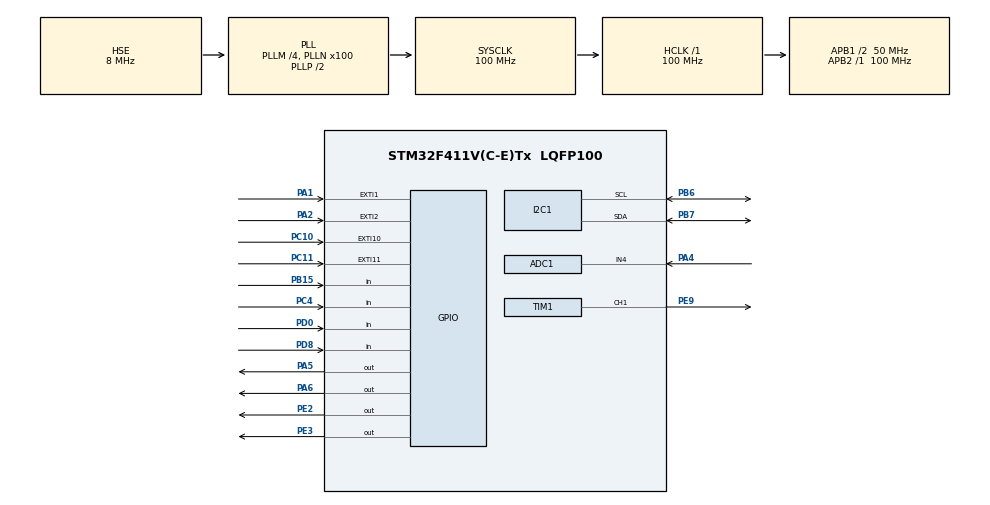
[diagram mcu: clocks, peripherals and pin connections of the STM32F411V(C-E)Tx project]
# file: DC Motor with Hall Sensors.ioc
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ADC1.Channel-0\#ChannelRegularConversion=ADC_CHANNEL_4
ADC1.ContinuousConvMode=ENABLE
ADC1.NbrOfConversion=1
ADC1.NbrOfConversionFlag=1
ADC1.Rank-0\#ChannelRegularConversion=1
ADC1.SamplingTime-0\#ChannelRegularConversion=ADC_SAMPLETIME_3CYCLES
ADC1.ScanConvMode=ENABLE
ADC1.master=1
Dma.ADC1.1.Direction=DMA_PERIPH_TO_MEMORY
Dma.ADC1.1.FIFOMode=DMA_FIFOMODE_DISABLE
Dma.ADC1.1.Instance=DMA2_Stream0
Dma.ADC1.1.MemDataAlignment=DMA_MDATAALIGN_WORD
Dma.ADC1.1.MemInc=DMA_MINC_ENABLE
Dma.ADC1.1.Mode=DMA_CIRCULAR
Dma.ADC1.1.PeriphDataAlignment=DMA_PDATAALIGN_WORD
Dma.ADC1.1.PeriphInc=DMA_PINC_DISABLE
Dma.ADC1.1.Priority=DMA_PRIORITY_LOW
Dma.Request0=TIM1_CH1
Dma.Request1=ADC1
Dma.TIM1_CH1.0.Direction=DMA_MEMORY_TO_PERIPH
Dma.TIM1_CH1.0.FIFOMode=DMA_FIFOMODE_DISABLE
Dma.TIM1_CH1.0.Instance=DMA2_Stream1
Dma.TIM1_CH1.0.MemDataAlignment=DMA_MDATAALIGN_HALFWORD
Dma.TIM1_CH1.0.MemInc=DMA_MINC_ENABLE
Dma.TIM1_CH1.0.Mode=DMA_NORMAL
Dma.TIM1_CH1.0.PeriphDataAlignment=DMA_PDATAALIGN_HALFWORD
Dma.TIM1_CH1.0.PeriphInc=DMA_PINC_DISABLE
Dma.TIM1_CH1.0.Priority=DMA_PRIORITY_LOW
Mcu.Family=STM32F4
Mcu.Name=STM32F411V(C-E)Tx
Mcu.Package=LQFP100
NVIC.ADC_IRQn=true\:0\:0\:false\:false\:true\:true\:true\:true
NVIC.DMA2_Stream0_IRQn=true\:0\:0\:false\:false\:true\:false\:true\:true
NVIC.DMA2_Stream1_IRQn=true\:0\:0\:false\:false\:true\:false\:true\:true
NVIC.EXTI15_10_IRQn=true\:0\:0\:false\:false\:true\:true\:true\:true
NVIC.EXTI1_IRQn=true\:0\:0\:false\:false\:true\:true\:true\:true
NVIC.EXTI2_IRQn=true\:0\:0\:false\:false\:true\:true\:true\:true
NVIC.PriorityGroup=NVIC_PRIORITYGROUP_4
NVIC.TIM1_BRK_TIM9_IRQn=true\:0\:0\:false\:false\:true\:true\:true\:true
NVIC.TIM2_IRQn=true\:0\:0\:false\:false\:true\:true\:true\:true
PA1.GPIO_ModeDefaultEXTI=GPIO_MODE_IT_RISING_FALLING
PA1.Signal=GPXTI1
PA13.Mode=Serial_Wire
PA13.Signal=SYS_JTMS-SWDIO
PA14.Mode=Serial_Wire
PA14.Signal=SYS_JTCK-SWCLK
PA2.GPIO_ModeDefaultEXTI=GPIO_MODE_IT_RISING_FALLING
PA2.Signal=GPXTI2
PA4.Signal=ADCx_IN4
PA5.Signal=GPIO_Output
PA6.Signal=GPIO_Output
PA7.Signal=ADCx_IN7
PB15.Signal=GPIO_Input
PB6.Mode=I2C
PB6.Signal=I2C1_SCL
PB7.Mode=I2C
PB7.Signal=I2C1_SDA
PC10.GPIO_ModeDefaultEXTI=GPIO_MODE_IT_RISING_FALLING
PC10.Signal=GPXTI10
PC11.GPIO_ModeDefaultEXTI=GPIO_MODE_IT_RISING_FALLING
PC11.Signal=GPXTI11
PC4.Signal=GPIO_Input
PD0.Signal=GPIO_Input
PD8.Signal=GPIO_Input
PE2.Signal=GPIO_Output
PE3.Signal=GPIO_Output
PE9.Signal=S_TIM1_CH1
PH0\ -\ OSC_IN.Mode=HSE-External-Oscillator
PH0\ -\ OSC_IN.Signal=RCC_OSC_IN
PH1\ -\ OSC_OUT.Mode=HSE-External-Oscillator
PH1\ -\ OSC_OUT.Signal=RCC_OSC_OUT
ProjectManager.HeapSize=0x200
ProjectManager.StackSize=0x400
ProjectManager.TargetToolchain=STM32CubeIDE
RCC.48MHZClocksFreq_Value=50000000
RCC.AHBFreq_Value=100000000
RCC.APB1CLKDivider=RCC_HCLK_DIV2
RCC.APB1Freq_Value=50000000
RCC.APB1TimFreq_Value=100000000
RCC.APB2Freq_Value=100000000
RCC.APB2TimFreq_Value=100000000
RCC.CortexFreq_Value=100000000
RCC.HCLKFreq_Value=100000000
RCC.HSE_VALUE=8000000
RCC.HSI_VALUE=16000000
RCC.LSE_VALUE=32768
RCC.PLLM=4
RCC.PLLN=100
RCC.PLLSourceVirtual=RCC_PLLSOURCE_HSE
RCC.SYSCLKFreq_VALUE=100000000
RCC.SYSCLKSource=RCC_SYSCLKSOURCE_PLLCLK
RCC.VCOOutputFreq_Value=200000000
SH.ADCx_IN4.0=ADC1_IN4,IN4
SH.ADCx_IN7.0=ADC1_IN7
SH.S_TIM1_CH1.0=TIM1_CH1,PWM Generation1 CH1
TIM1.Channel-PWM\ Generation1\ CH1=TIM_CHANNEL_1
TIM1.Period=100-1
TIM1.Prescaler=100-1
TIM2.AutoReloadPreload=TIM_AUTORELOAD_PRELOAD_ENABLE
TIM2.Period=10-1
TIM2.Prescaler=100-1
TIM2.TIM_MasterOutputTrigger=TIM_TRGO_RESET
TIM9.Period=10-1
TIM9.Prescaler=10-1
VP_TIM1_VS_ClockSourceINT.Mode=Internal
VP_TIM2_VS_ClockSourceINT.Mode=Internal
VP_TIM9_VS_ClockSourceINT.Mode=Internal
board=custom

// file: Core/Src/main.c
/* USER CODE BEGIN Header */
/**
  ******************************************************************************
  * @file           : main.c
  * @brief          : Main program body
  ******************************************************************************
  * @attention
  *
  * Copyright (c) 2023 STMicroelectronics.
  * All rights reserved.
  *
  * This software is licensed under terms that can be found in the LICENSE file
  * in the root directory of this software component.
  * If no LICENSE file comes with this software, it is provided AS-IS.
  *
  ******************************************************************************
  */
/* USER CODE END Header */
#include "main.h"

ADC_HandleTypeDef hadc1;
DMA_HandleTypeDef hdma_adc1;

I2C_HandleTypeDef hi2c1;

TIM_HandleTypeDef htim1;
TIM_HandleTypeDef htim2;
TIM_HandleTypeDef htim9;
DMA_HandleTypeDef hdma_tim1_ch1;

void SystemClock_Config(void);
static void MX_GPIO_Init(void);
static void MX_DMA_Init(void);
static void MX_TIM1_Init(void);
static void MX_ADC1_Init(void);
static void MX_I2C1_Init(void);
static void MX_TIM2_Init(void);
static void MX_TIM9_Init(void);

int main(void)
{

  /* MCU Configuration--------------------------------------------------------*/

  /* Reset of all peripherals, Initializes the Flash interface and the Systick. */
  HAL_Init();

  /* Configure the system clock */
  SystemClock_Config();

  /* Initialize all configured peripherals */
  MX_GPIO_Init();
  MX_DMA_Init();
  MX_TIM1_Init();
  MX_ADC1_Init();
  MX_I2C1_Init();
  MX_TIM2_Init();
  MX_TIM9_Init();
  /* USER CODE BEGIN 2 */
  MotorCtrl_Main_Init();
  /* USER CODE END 2 */

  /* Infinite loop */
  while (1)
  {
	  MotorCtrl_Main_Task();
  }
}

void SystemClock_Config(void)
{
  RCC_OscInitTypeDef RCC_OscInitStruct = {0};
  RCC_ClkInitTypeDef RCC_ClkInitStruct = {0};

  /** Configure the main internal regulator output voltage
  */
  __HAL_RCC_PWR_CLK_ENABLE();
  __HAL_PWR_VOLTAGESCALING_CONFIG(PWR_REGULATOR_VOLTAGE_SCALE1);

  /** Initializes the RCC Oscillators according to the specified parameters
  * in the RCC_OscInitTypeDef structure.
  */
  RCC_OscInitStruct.OscillatorType = RCC_OSCILLATORTYPE_HSE;
  RCC_OscInitStruct.HSEState = RCC_HSE_ON;
  RCC_OscInitStruct.PLL.PLLState = RCC_PLL_ON;
  RCC_OscInitStruct.PLL.PLLSource = RCC_PLLSOURCE_HSE;
  RCC_OscInitStruct.PLL.PLLM = 4;
  RCC_OscInitStruct.PLL.PLLN = 100;
  RCC_OscInitStruct.PLL.PLLP = RCC_PLLP_DIV2;
  RCC_OscInitStruct.PLL.PLLQ = 4;
  if (HAL_RCC_OscConfig(&RCC_OscInitStruct) != HAL_OK)
  {
    Error_Handler();
  }

  /** Initializes the CPU, AHB and APB buses clocks
  */
  RCC_ClkInitStruct.ClockType = RCC_CLOCKTYPE_HCLK|RCC_CLOCKTYPE_SYSCLK
                              |RCC_CLOCKTYPE_PCLK1|RCC_CLOCKTYPE_PCLK2;
  RCC_ClkInitStruct.SYSCLKSource = RCC_SYSCLKSOURCE_PLLCLK;
  RCC_ClkInitStruct.AHBCLKDivider = RCC_SYSCLK_DIV1;
  RCC_ClkInitStruct.APB1CLKDivider = RCC_HCLK_DIV2;
  RCC_ClkInitStruct.APB2CLKDivider = RCC_HCLK_DIV1;

  if (HAL_RCC_ClockConfig(&RCC_ClkInitStruct, FLASH_LATENCY_3) != HAL_OK)
  {
    Error_Handler();
  }
}

static void MX_ADC1_Init(void)
{

  ADC_ChannelConfTypeDef sConfig = {0};

  /** Configure the global features of the ADC (Clock, Resolution, Data Alignment and number of conversion)
  */
  hadc1.Instance = ADC1;
  hadc1.Init.ClockPrescaler = ADC_CLOCK_SYNC_PCLK_DIV4;
  hadc1.Init.Resolution = ADC_RESOLUTION_12B;
  hadc1.Init.ScanConvMode = ENABLE;
  hadc1.Init.ContinuousConvMode = ENABLE;
  hadc1.Init.DiscontinuousConvMode = DISABLE;
  hadc1.Init.ExternalTrigConvEdge = ADC_EXTERNALTRIGCONVEDGE_NONE;
  hadc1.Init.ExternalTrigConv = ADC_SOFTWARE_START;
  hadc1.Init.DataAlign = ADC_DATAALIGN_RIGHT;
  hadc1.Init.NbrOfConversion = 1;
  hadc1.Init.DMAContinuousRequests = DISABLE;
  hadc1.Init.EOCSelection = ADC_EOC_SINGLE_CONV;
  if (HAL_ADC_Init(&hadc1) != HAL_OK)
  {
    Error_Handler();
  }

  /** Configure for the selected ADC regular channel its corresponding rank in the sequencer and its sample time.
  */
  sConfig.Channel = ADC_CHANNEL_4;
  sConfig.Rank = 1;
  sConfig.SamplingTime = ADC_SAMPLETIME_3CYCLES;
  if (HAL_ADC_ConfigChannel(&hadc1, &sConfig) != HAL_OK)
  {
    Error_Handler();
  }

}

static void MX_I2C1_Init(void)
{

  hi2c1.Instance = I2C1;
  hi2c1.Init.ClockSpeed = 100000;
  hi2c1.Init.DutyCycle = I2C_DUTYCYCLE_2;
  hi2c1.Init.OwnAddress1 = 0;
  hi2c1.Init.AddressingMode = I2C_ADDRESSINGMODE_7BIT;
  hi2c1.Init.DualAddressMode = I2C_DUALADDRESS_DISABLE;
  hi2c1.Init.OwnAddress2 = 0;
  hi2c1.Init.GeneralCallMode = I2C_GENERALCALL_DISABLE;
  hi2c1.Init.NoStretchMode = I2C_NOSTRETCH_DISABLE;
  if (HAL_I2C_Init(&hi2c1) != HAL_OK)
  {
    Error_Handler();
  }

}

static void MX_TIM1_Init(void)
{

  TIM_ClockConfigTypeDef sClockSourceConfig = {0};
  TIM_MasterConfigTypeDef sMasterConfig = {0};
  TIM_OC_InitTypeDef sConfigOC = {0};
  TIM_BreakDeadTimeConfigTypeDef sBreakDeadTimeConfig = {0};

  htim1.Instance = TIM1;
  htim1.Init.Prescaler = 100-1;
  htim1.Init.CounterMode = TIM_COUNTERMODE_UP;
  htim1.Init.Period = 100-1;
  htim1.Init.ClockDivision = TIM_CLOCKDIVISION_DIV1;
  htim1.Init.RepetitionCounter = 0;
  htim1.Init.AutoReloadPreload = TIM_AUTORELOAD_PRELOAD_DISABLE;
  if (HAL_TIM_Base_Init(&htim1) != HAL_OK)
  {
    Error_Handler();
  }
  sClockSourceConfig.ClockSource = TIM_CLOCKSOURCE_INTERNAL;
  if (HAL_TIM_ConfigClockSource(&htim1, &sClockSourceConfig) != HAL_OK)
  {
    Error_Handler();
  }
  if (HAL_TIM_PWM_Init(&htim1) != HAL_OK)
  {
    Error_Handler();
  }
  sMasterConfig.MasterOutputTrigger = TIM_TRGO_RESET;
  sMasterConfig.MasterSlaveMode = TIM_MASTERSLAVEMODE_DISABLE;
  if (HAL_TIMEx_MasterConfigSynchronization(&htim1, &sMasterConfig) != HAL_OK)
  {
    Error_Handler();
  }
  sConfigOC.OCMode = TIM_OCMODE_PWM1;
  sConfigOC.Pulse = 0;
  sConfigOC.OCPolarity = TIM_OCPOLARITY_HIGH;
  sConfigOC.OCNPolarity = TIM_OCNPOLARITY_HIGH;
  sConfigOC.OCFastMode = TIM_OCFAST_DISABLE;
  sConfigOC.OCIdleState = TIM_OCIDLESTATE_RESET;
  sConfigOC.OCNIdleState = TIM_OCNIDLESTATE_RESET;
  if (HAL_TIM_PWM_ConfigChannel(&htim1, &sConfigOC, TIM_CHANNEL_1) != HAL_OK)
  {
    Error_Handler();
  }
  sBreakDeadTimeConfig.OffStateRunMode = TIM_OSSR_DISABLE;
  sBreakDeadTimeConfig.OffStateIDLEMode = TIM_OSSI_DISABLE;
  sBreakDeadTimeConfig.LockLevel = TIM_LOCKLEVEL_OFF;
  sBreakDeadTimeConfig.DeadTime = 0;
  sBreakDeadTimeConfig.BreakState = TIM_BREAK_DISABLE;
  sBreakDeadTimeConfig.BreakPolarity = TIM_BREAKPOLARITY_HIGH;
  sBreakDeadTimeConfig.AutomaticOutput = TIM_AUTOMATICOUTPUT_DISABLE;
  if (HAL_TIMEx_ConfigBreakDeadTime(&htim1, &sBreakDeadTimeConfig) != HAL_OK)
  {
    Error_Handler();
  }
  HAL_TIM_MspPostInit(&htim1);

}

static void MX_TIM2_Init(void)
{

  TIM_ClockConfigTypeDef sClockSourceConfig = {0};
  TIM_MasterConfigTypeDef sMasterConfig = {0};

  htim2.Instance = TIM2;
  htim2.Init.Prescaler = 100-1;
  htim2.Init.CounterMode = TIM_COUNTERMODE_UP;
  htim2.Init.Period = 10-1;
  htim2.Init.ClockDivision = TIM_CLOCKDIVISION_DIV1;
  htim2.Init.AutoReloadPreload = TIM_AUTORELOAD_PRELOAD_ENABLE;
  if (HAL_TIM_Base_Init(&htim2) != HAL_OK)
  {
    Error_Handler();
  }
  sClockSourceConfig.ClockSource = TIM_CLOCKSOURCE_INTERNAL;
  if (HAL_TIM_ConfigClockSource(&htim2, &sClockSourceConfig) != HAL_OK)
  {
    Error_Handler();
  }
  sMasterConfig.MasterOutputTrigger = TIM_TRGO_RESET;
  sMasterConfig.MasterSlaveMode = TIM_MASTERSLAVEMODE_DISABLE;
  if (HAL_TIMEx_MasterConfigSynchronization(&htim2, &sMasterConfig) != HAL_OK)
  {
    Error_Handler();
  }

}

static void MX_TIM9_Init(void)
{

  TIM_ClockConfigTypeDef sClockSourceConfig = {0};

  htim9.Instance = TIM9;
  htim9.Init.Prescaler = 10-1;
  htim9.Init.CounterMode = TIM_COUNTERMODE_UP;
  htim9.Init.Period = 10-1;
  htim9.Init.ClockDivision = TIM_CLOCKDIVISION_DIV1;
  htim9.Init.AutoReloadPreload = TIM_AUTORELOAD_PRELOAD_DISABLE;
  if (HAL_TIM_Base_Init(&htim9) != HAL_OK)
  {
    Error_Handler();
  }
  sClockSourceConfig.ClockSource = TIM_CLOCKSOURCE_INTERNAL;
  if (HAL_TIM_ConfigClockSource(&htim9, &sClockSourceConfig) != HAL_OK)
  {
    Error_Handler();
  }

}

static void MX_DMA_Init(void)
{

  /* DMA controller clock enable */
  __HAL_RCC_DMA2_CLK_ENABLE();

  /* DMA interrupt init */
  /* DMA2_Stream0_IRQn interrupt configuration */
  HAL_NVIC_SetPriority(DMA2_Stream0_IRQn, 0, 0);
  HAL_NVIC_EnableIRQ(DMA2_Stream0_IRQn);
  /* DMA2_Stream1_IRQn interrupt configuration */
  HAL_NVIC_SetPriority(DMA2_Stream1_IRQn, 0, 0);
  HAL_NVIC_EnableIRQ(DMA2_Stream1_IRQn);

}

static void MX_GPIO_Init(void)
{
  GPIO_InitTypeDef GPIO_InitStruct = {0};

  /* GPIO Ports Clock Enable */
  __HAL_RCC_GPIOE_CLK_ENABLE();
  __HAL_RCC_GPIOH_CLK_ENABLE();
  __HAL_RCC_GPIOA_CLK_ENABLE();
  __HAL_RCC_GPIOC_CLK_ENABLE();
  __HAL_RCC_GPIOB_CLK_ENABLE();
  __HAL_RCC_GPIOD_CLK_ENABLE();

  /*Configure GPIO pin Output Level */
  HAL_GPIO_WritePin(GPIOE, GPIO_PIN_2|GPIO_PIN_3, GPIO_PIN_RESET);

  /*Configure GPIO pin Output Level */
  HAL_GPIO_WritePin(GPIOA, GPIO_PIN_5|GPIO_PIN_6, GPIO_PIN_RESET);

  /*Configure GPIO pins : PE2 PE3 */
  GPIO_InitStruct.Pin = GPIO_PIN_2|GPIO_PIN_3;
  GPIO_InitStruct.Mode = GPIO_MODE_OUTPUT_PP;
  GPIO_InitStruct.Pull = GPIO_NOPULL;
  GPIO_InitStruct.Speed = GPIO_SPEED_FREQ_LOW;
  HAL_GPIO_Init(GPIOE, &GPIO_InitStruct);

  /*Configure GPIO pins : PA1 PA2 */
  GPIO_InitStruct.Pin = GPIO_PIN_1|GPIO_PIN_2;
  GPIO_InitStruct.Mode = GPIO_MODE_IT_RISING_FALLING;
  GPIO_InitStruct.Pull = GPIO_NOPULL;
  HAL_GPIO_Init(GPIOA, &GPIO_InitStruct);

  /*Configure GPIO pins : PA5 PA6 */
  GPIO_InitStruct.Pin = GPIO_PIN_5|GPIO_PIN_6;
  GPIO_InitStruct.Mode = GPIO_MODE_OUTPUT_PP;
  GPIO_InitStruct.Pull = GPIO_NOPULL;
  GPIO_InitStruct.Speed = GPIO_SPEED_FREQ_LOW;
  HAL_GPIO_Init(GPIOA, &GPIO_InitStruct);

  /*Configure GPIO pin : PC4 */
  GPIO_InitStruct.Pin = GPIO_PIN_4;
  GPIO_InitStruct.Mode = GPIO_MODE_INPUT;
  GPIO_InitStruct.Pull = GPIO_NOPULL;
  HAL_GPIO_Init(GPIOC, &GPIO_InitStruct);

  /*Configure GPIO pin : PB15 */
  GPIO_InitStruct.Pin = GPIO_PIN_15;
  GPIO_InitStruct.Mode = GPIO_MODE_INPUT;
  GPIO_InitStruct.Pull = GPIO_NOPULL;
  HAL_GPIO_Init(GPIOB, &GPIO_InitStruct);

  /*Configure GPIO pins : PD8 PD0 */
  GPIO_InitStruct.Pin = GPIO_PIN_8|GPIO_PIN_0;
  GPIO_InitStruct.Mode = GPIO_MODE_INPUT;
  GPIO_InitStruct.Pull = GPIO_NOPULL;
  HAL_GPIO_Init(GPIOD, &GPIO_InitStruct);

  /*Configure GPIO pins : PC10 PC11 */
  GPIO_InitStruct.Pin = GPIO_PIN_10|GPIO_PIN_11;
  GPIO_InitStruct.Mode = GPIO_MODE_IT_RISING_FALLING;
  GPIO_InitStruct.Pull = GPIO_NOPULL;
  HAL_GPIO_Init(GPIOC, &GPIO_InitStruct);

  /* EXTI interrupt init*/
  HAL_NVIC_SetPriority(EXTI1_IRQn, 0, 0);
  HAL_NVIC_EnableIRQ(EXTI1_IRQn);

  HAL_NVIC_SetPriority(EXTI2_IRQn, 0, 0);
  HAL_NVIC_EnableIRQ(EXTI2_IRQn);

  HAL_NVIC_SetPriority(EXTI15_10_IRQn, 0, 0);
  HAL_NVIC_EnableIRQ(EXTI15_10_IRQn);

}

void Error_Handler(void)
{
  __disable_irq();
  while (1)
  {
  }
}
